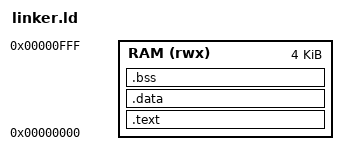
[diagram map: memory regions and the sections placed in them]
OUTPUT_ARCH("riscv")
ENTRY(_start)

MEMORY
{
    RAM (rwx) : ORIGIN = 0x00000000, LENGTH = 4K
}

SECTIONS
{
    .text : {
        *(.text)
        *(.text.*)
    } > RAM

    .data : {
        *(.data)
        *(.data.*)
    } > RAM

    .bss : {
        *(.bss)
        *(.bss.*)
    } > RAM
}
